VERSION ""

NS_ :

BS_:
BU_: cananddevice

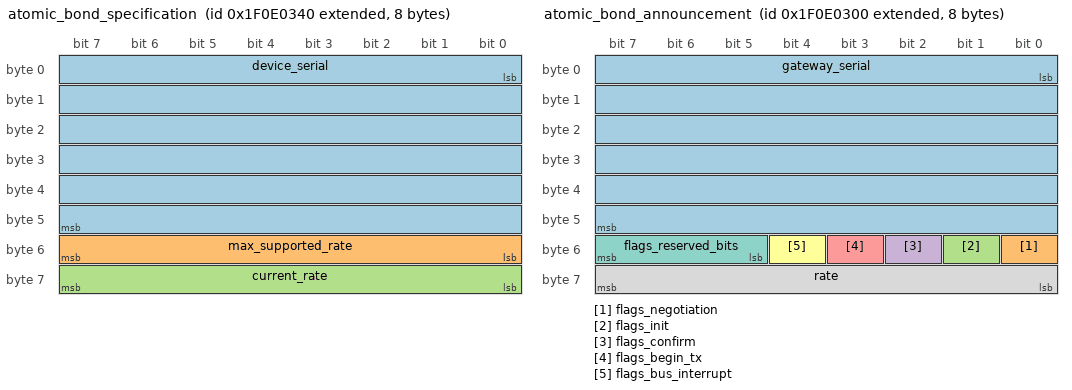
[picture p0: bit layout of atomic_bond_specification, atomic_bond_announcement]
BO_ 2668495680 atomic_bond_specification: 8 cananddevice
 SG_ device_serial : 0|48@1+ (1,0) [0|281474976710655] "" Vector__XXX
 SG_ max_supported_rate : 48|8@1+ (1,0) [0|255] "" Vector__XXX
 SG_ current_rate : 56|8@1+ (1,0) [0|255] "" Vector__XXX

BO_ 2668495616 atomic_bond_announcement: 8 Vector__XXX
 SG_ gateway_serial : 0|48@1+ (1,0) [0|281474976710655] "" cananddevice
 SG_ flags_negotiation : 48|1@1+ (1,0) [0|1] "" cananddevice
 SG_ flags_init : 49|1@1+ (1,0) [0|1] "" cananddevice
 SG_ flags_confirm : 50|1@1+ (1,0) [0|1] "" cananddevice
 SG_ flags_begin_tx : 51|1@1+ (1,0) [0|1] "" cananddevice
 SG_ flags_bus_interrupt : 52|1@1+ (1,0) [0|1] "" cananddevice
 SG_ flags_reserved_bits : 53|3@1+ (1,0) [0|7] "" cananddevice
 SG_ rate : 56|8@1+ (1,0) [0|255] "" cananddevice

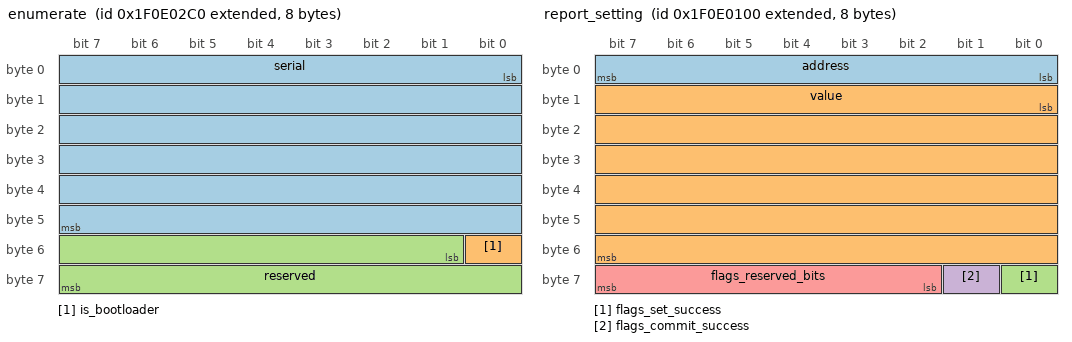
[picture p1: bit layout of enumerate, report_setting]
BO_ 2668495552 enumerate: 8 cananddevice
 SG_ serial : 0|48@1+ (1,0) [0|281474976710655] "" Vector__XXX
 SG_ is_bootloader : 48|1@1+ (1,0) [0|1] "" Vector__XXX
 SG_ reserved : 49|15@1+ (1,0) [0|32767] "" Vector__XXX

BO_ 2668495488 ota_to_device: 8 Vector__XXX
 SG_ to_device_data : 0|64@1+ (1,0) [0|18446744073709551615] "" cananddevice

BO_ 2668495424 ota_to_host: 8 cananddevice
 SG_ to_host_data : 0|64@1+ (1,0) [0|18446744073709551615] "" Vector__XXX

BO_ 2668495360 ota_data: 8 Vector__XXX
 SG_ data : 0|64@1+ (1,0) [0|18446744073709551615] "" cananddevice

BO_ 2668495296 party_mode: 8 Vector__XXX
 SG_ party_level : 0|8@1+ (1,0) [0|255] "" cananddevice

BO_ 2668495232 status: 8 cananddevice
 SG_ dev_specific : 0|64@1+ (1,0) [0|18446744073709551615] "" Vector__XXX

BO_ 2668495168 clear_sticky_faults: 8 Vector__XXX

BO_ 2668495104 report_setting: 8 cananddevice
 SG_ address : 0|8@1+ (1,0) [0|255] "" Vector__XXX
 SG_ value : 8|48@1+ (1,0) [0|281474976710655] "" Vector__XXX
 SG_ flags_set_success : 56|1@1+ (1,0) [0|1] "" Vector__XXX
 SG_ flags_commit_success : 57|1@1+ (1,0) [0|1] "" Vector__XXX
 SG_ flags_reserved_bits : 58|6@1+ (1,0) [0|63] "" Vector__XXX

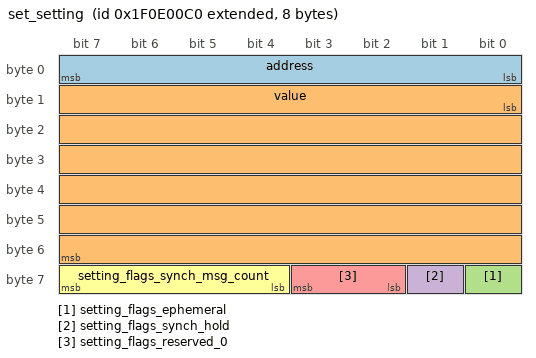
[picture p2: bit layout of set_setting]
BO_ 2668495040 set_setting: 8 Vector__XXX
 SG_ address : 0|8@1+ (1,0) [0|255] "" cananddevice
 SG_ value : 8|48@1+ (1,0) [0|281474976710655] "" cananddevice
 SG_ setting_flags_ephemeral : 56|1@1+ (1,0) [0|1] "" cananddevice
 SG_ setting_flags_synch_hold : 57|1@1+ (1,0) [0|1] "" cananddevice
 SG_ setting_flags_reserved_0 : 58|2@1+ (1,0) [0|3] "" cananddevice
 SG_ setting_flags_synch_msg_count : 60|4@1+ (1,0) [0|15] "" cananddevice

BO_ 2668494976 setting_command: 8 Vector__XXX
 SG_ control_flag : 0|8@1+ (1,0) [0|255] "" cananddevice
 SG_ setting_index : 8|8@1+ (1,0) [0|255] "" cananddevice

BO_ 2668494912 can_id_error: 8 cananddevice
 SG_ addr_value : 0|64@1+ (1,0) [0|18446744073709551615] "" Vector__XXX

BO_ 2668494848 can_id_arbitrate: 8 Vector__XXX
 SG_ addr_value : 0|64@1+ (1,0) [0|18446744073709551615] "" cananddevice

CM_ BO_ 2668495680 atomic_bond_specification "Atomic bond specification. Sent by devices to announce capabilities.";
CM_ SG_ 2668495680 device_serial "Device's unique serial number";
CM_ SG_ 2668495680 max_supported_rate "Supported bus rates";
CM_ SG_ 2668495680 current_rate "Current bus rate, if confirming";
CM_ BO_ 2668495616 atomic_bond_announcement "Atomic bond announcement. Sent by gateway to control bus state, and by devices during negotiation.";
CM_ SG_ 2668495616 gateway_serial "Gateway's unique serial number";
CM_ SG_ 2668495616 flags_negotiation "Device should enter negotiation phase";
CM_ SG_ 2668495616 flags_init "Device should initialize bus with new rate";
CM_ SG_ 2668495616 flags_confirm "Device should confirm new bus rate";
CM_ SG_ 2668495616 flags_begin_tx "Device should begin transmission";
CM_ SG_ 2668495616 flags_bus_interrupt "Device should cease all transmission";
CM_ SG_ 2668495616 flags_reserved_bits "Announcement Flags";
CM_ SG_ 2668495616 rate "New bus rate for initialization";
CM_ BO_ 2668495552 enumerate "Device enumerate response";
CM_ SG_ 2668495552 serial "Device-unique serial number";
CM_ SG_ 2668495552 is_bootloader "Device is in bootloader.";
CM_ SG_ 2668495552 reserved "Reserved";
CM_ BO_ 2668495488 ota_to_device "Firmware update command.";
CM_ SG_ 2668495488 to_device_data "OTA to device data (dlc may vary)";
CM_ BO_ 2668495424 ota_to_host "Firmware update response.";
CM_ SG_ 2668495424 to_host_data "OTA to host data (dlc may vary)";
CM_ BO_ 2668495360 ota_data "Firmware update payload";
CM_ SG_ 2668495360 data "OTA data";
CM_ BO_ 2668495296 party_mode "Party mode";
CM_ SG_ 2668495296 party_level "Party level. 0 disables the strobe, whereas 1 enables it.";
CM_ BO_ 2668495232 status "Status frame";
CM_ SG_ 2668495232 dev_specific "Device-specific status data. See device pages for more information.";
CM_ BO_ 2668495168 clear_sticky_faults "Clear device sticky faults";
CM_ BO_ 2668495104 report_setting "setting value report from device";
CM_ SG_ 2668495104 address "Setting index to write to";
CM_ SG_ 2668495104 value "6-byte setting value";
CM_ SG_ 2668495104 flags_set_success "Whether the setting set/fetch was successful";
CM_ SG_ 2668495104 flags_commit_success "Whether the setting synch commit was successful";
CM_ SG_ 2668495104 flags_reserved_bits "Setting receive status";
CM_ BO_ 2668495040 set_setting "update setting on device";
CM_ SG_ 2668495040 address "Setting index to write to";
CM_ SG_ 2668495040 value "6-byte setting value";
CM_ SG_ 2668495040 setting_flags_ephemeral "Whether the setting should be set ephemeral";
CM_ SG_ 2668495040 setting_flags_synch_hold "Whether the setting should be held until the next synch barrier";
CM_ SG_ 2668495040 setting_flags_reserved_0 "Reserved";
CM_ SG_ 2668495040 setting_flags_synch_msg_count "Synch message count";
CM_ BO_ 2668494976 setting_command "setting control command";
CM_ SG_ 2668494976 control_flag "Setting command index";
CM_ SG_ 2668494976 setting_index "setting index to fetch";
CM_ BO_ 2668494912 can_id_error "can id conflict tx packet";
CM_ SG_ 2668494912 addr_value "Device-unique value that can be used during arbitration";
CM_ BO_ 2668494848 can_id_arbitrate "select conflicting device to use";
CM_ SG_ 2668494848 addr_value "Value corresponding to what was broadcasted in the CAN_ID_ERROR packet";
